# MK81F25615 register map
Vendor: Freescale Semiconductor, Inc.; Series: Kinetis_K; File version: 1.6
CPU: CM4 r0p1, little endian, no MPU, FPU, VTOR, 4 interrupt priority bits
Registers are 32-bit, read-write, reset 0x0 unless marked. A register's access mark holds for its fields unless they carry their own. Offsets are from the block's base; [hi:lo] are bit positions; {n}, {i} and the like mark numbered series; 'fields as' and 'values as' point back to an identical list.

## GPIOA — General Purpose Input/Output
Base 0x400FF000; register names take the prefix GPIOA_
0x00 PDOR — Port Data Output Register
  [31:0] PDO — Port Data Output
    0=Logic level 0 is driven on pin, provided pin is configured for general-purpose output; 1=Logic level 1 is driven on pin, provided pin is configured for general-purpose output
0x04 PSOR wo — Port Set Output Register
  [31:0] PTSO — Port Set Output
    0=Corresponding bit in PDORn does not change; 1=Corresponding bit in PDORn is set to logic 1
0x08 PCOR wo — Port Clear Output Register
  [31:0] PTCO — Port Clear Output
    0=Corresponding bit in PDORn does not change; 1=Corresponding bit in PDORn is cleared to logic 0
0x0C PTOR wo — Port Toggle Output Register
  [31:0] PTTO — Port Toggle Output
    0=Corresponding bit in PDORn does not change; 1=Corresponding bit in PDORn is set to the inverse of its existing logic state
0x10 PDIR ro — Port Data Input Register
  [31:0] PDI — Port Data Input
    0=Pin logic level is logic 0, or is not configured for use by digital function; 1=Pin logic level is logic 1
0x14 PDDR — Port Data Direction Register
  [31:0] PDD — Port Data Direction
    0=Pin is configured as general-purpose input, for the GPIO function; 1=Pin is configured as general-purpose output, for the GPIO function

## GPIOB — General Purpose Input/Output
Base 0x400FF040; register names take the prefix GPIOB_
Registers as GPIOA.

## GPIOC — General Purpose Input/Output
Base 0x400FF080; register names take the prefix GPIOC_
Registers as GPIOA.

## GPIOD — General Purpose Input/Output
Base 0x400FF0C0; register names take the prefix GPIOD_
Registers as GPIOA.

## GPIOE — General Purpose Input/Output
Base 0x400FF100; register names take the prefix GPIOE_
Registers as GPIOA.

## CAU — Memory Mapped Cryptographic Acceleration Unit (MMCAU)
Base 0xE0081000
{0x0+4i} CAU_DIRECT{i} wo (i=0..15) — Direct access register {i}
  [31:0] CAU_DIRECT{i} — Direct register {i}
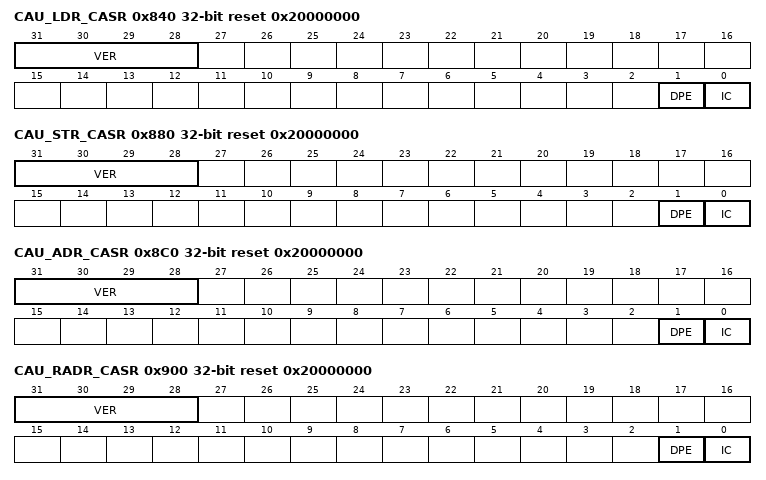
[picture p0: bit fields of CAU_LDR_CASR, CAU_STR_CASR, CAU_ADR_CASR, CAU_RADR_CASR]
0x840 CAU_LDR_CASR wo reset 0x20000000 — Status register - Load Register command
  [31:28] VER — CAU version
    1=Initial CAU version; 2=Second version, added support for SHA-256 algorithm.(This is the value on this device)
  [1] DPE
    0=No error detected; 1=DES key parity error detected
  [0] IC
    0=No illegal commands issued; 1=Illegal command issued
0x844 CAU_LDR_CAA wo — Accumulator register - Load Register command
  [31:0] ACC
{0x848+4i} CAU_LDR_CA{i} wo (i=0..8) — General Purpose Register {i} - Load Register command
0x880 CAU_STR_CASR ro reset 0x20000000 — Status register - Store Register command
  fields as CAU_LDR_CASR
0x884 CAU_STR_CAA ro — Accumulator register - Store Register command
  [31:0] ACC
{0x888+4i} CAU_STR_CA{i} ro (i=0..8) — General Purpose Register {i} - Store Register command
0x8C0 CAU_ADR_CASR wo reset 0x20000000 — Status register - Add Register command
  fields as CAU_LDR_CASR
0x8C4 CAU_ADR_CAA wo — Accumulator register - Add to register command
  [31:0] ACC
{0x8C8+4i} CAU_ADR_CA{i} wo (i=0..8) — General Purpose Register {i} - Add to register command
0x900 CAU_RADR_CASR wo reset 0x20000000 — Status register - Reverse and Add to Register command
  fields as CAU_LDR_CASR
0x904 CAU_RADR_CAA wo — Accumulator register - Reverse and Add to Register command
  [31:0] ACC
{0x908+4i} CAU_RADR_CA{i} wo (i=0..8) — General Purpose Register {i} - Reverse and Add to Register command
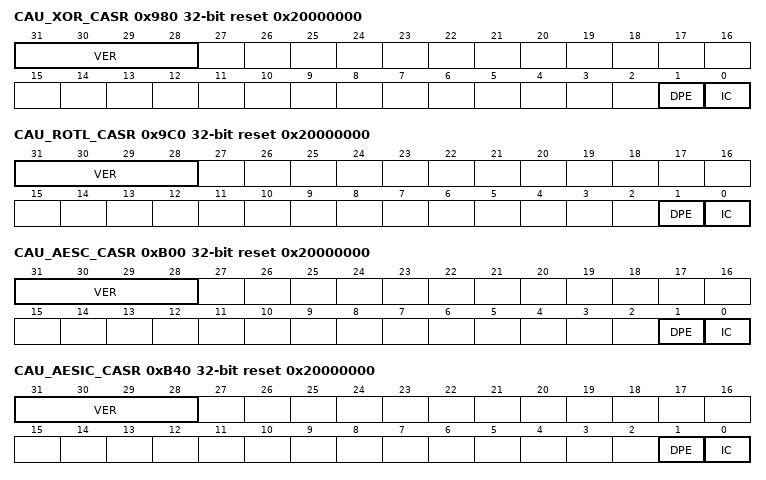
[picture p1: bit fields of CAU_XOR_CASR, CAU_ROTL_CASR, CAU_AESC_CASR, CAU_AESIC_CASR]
0x980 CAU_XOR_CASR wo reset 0x20000000 — Status register - Exclusive Or command
  fields as CAU_LDR_CASR
0x984 CAU_XOR_CAA wo — Accumulator register - Exclusive Or command
  [31:0] ACC
{0x988+4i} CAU_XOR_CA{i} wo (i=0..8) — General Purpose Register {i} - Exclusive Or command
0x9C0 CAU_ROTL_CASR wo reset 0x20000000 — Status register - Rotate Left command
  fields as CAU_LDR_CASR
0x9C4 CAU_ROTL_CAA wo — Accumulator register - Rotate Left command
  [31:0] ACC
{0x9C8+4i} CAU_ROTL_CA{i} wo (i=0..8) — General Purpose Register {i} - Rotate Left command
0xB00 CAU_AESC_CASR wo reset 0x20000000 — Status register - AES Column Operation command
  fields as CAU_LDR_CASR
0xB04 CAU_AESC_CAA wo — Accumulator register - AES Column Operation command
  [31:0] ACC
{0xB08+4i} CAU_AESC_CA{i} wo (i=0..8) — General Purpose Register {i} - AES Column Operation command
0xB40 CAU_AESIC_CASR wo reset 0x20000000 — Status register - AES Inverse Column Operation command
  fields as CAU_LDR_CASR
0xB44 CAU_AESIC_CAA wo — Accumulator register - AES Inverse Column Operation command
  [31:0] ACC
{0xB48+4i} CAU_AESIC_CA{i} wo (i=0..8) — General Purpose Register {i} - AES Inverse Column Operation command

## LMEM — Local Memory Controller
Base 0xE0082000; register names take the prefix LMEM_
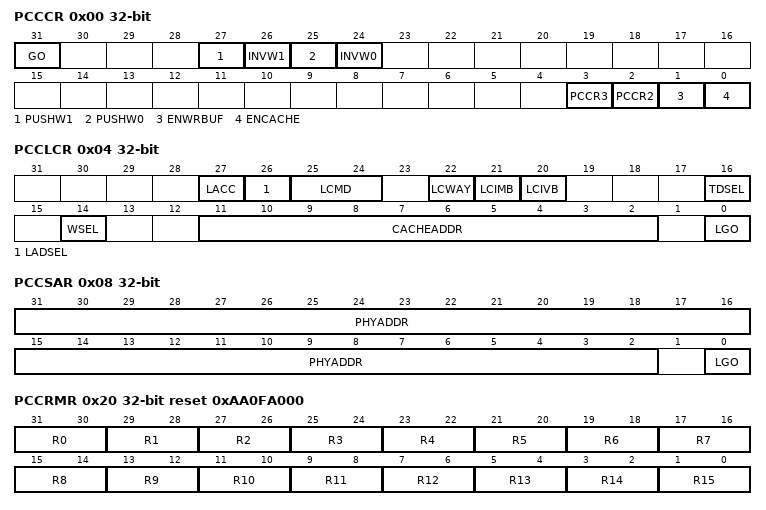
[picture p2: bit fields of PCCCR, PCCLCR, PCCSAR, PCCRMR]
0x00 PCCCR — Cache control register
  [31] GO — Initiate Cache Command
    0=Write: no effect. Read: no cache command active.; 1=Write: initiate command indicated by bits 27-24. Read: cache command active.
  [27] PUSHW1 — Push Way 1
    0=No operation; 1=When setting the GO bit, push all modified lines in way 1
  [26] INVW1 — Invalidate Way 1
    0=No operation; 1=When setting the GO bit, invalidate all lines in way 1
  [25] PUSHW0 — Push Way 0
    0=No operation; 1=When setting the GO bit, push all modified lines in way 0
  [24] INVW0 — Invalidate Way 0
    0=No operation; 1=When setting the GO bit, invalidate all lines in way 0
  [3] PCCR3 — Forces no allocation on cache misses (must also have PCCR2 asserted)
  [2] PCCR2 — Forces all cacheable spaces to write through
  [1] ENWRBUF — Enable Write Buffer
    0=Write buffer disabled; 1=Write buffer enabled
  [0] ENCACHE — Cache enable
    0=Cache disabled; 1=Cache enabled
0x04 PCCLCR — Cache line control register
  [27] LACC — Line access type
    0=Read; 1=Write
  [26] LADSEL — Line Address Select
    0=Cache address; 1=Physical address
  [25:24] LCMD — Line Command
    0=Search and read or write; 1=Invalidate; 2=Push; 3=Clear
  [22] LCWAY ro — Line Command Way
  [21] LCIMB ro — Line Command Initial Modified Bit
  [20] LCIVB ro — Line Command Initial Valid Bit
  [16] TDSEL — Tag/Data Select
    0=Data; 1=Tag
  [14] WSEL — Way select
    0=Way 0; 1=Way 1
  [11:2] CACHEADDR — Cache address
  [0] LGO — Initiate Cache Line Command
    0=Write: no effect. Read: no line command active.; 1=Write: initiate line command indicated by bits 27-24. Read: line command active.
0x08 PCCSAR — Cache search address register
  [31:2] PHYADDR — Physical Address
  [0] LGO — Initiate Cache Line Command
    0=Write: no effect. Read: no line command active.; 1=Write: initiate line command indicated by bits CLCR[27:24]. Read: line command active.
0x0C PCCCVR — Cache read/write value register
  [31:0] DATA — Cache read/write Data
0x20 PCCRMR reset 0xAA0FA000 — Cache regions mode register
  [all] fields
    0=Non-cacheable; 1=Non-cacheable; 2=Write-through; 3=Write-back
  [31-2n:30-2n] R{n} (n=0..15) — Region {n} mode
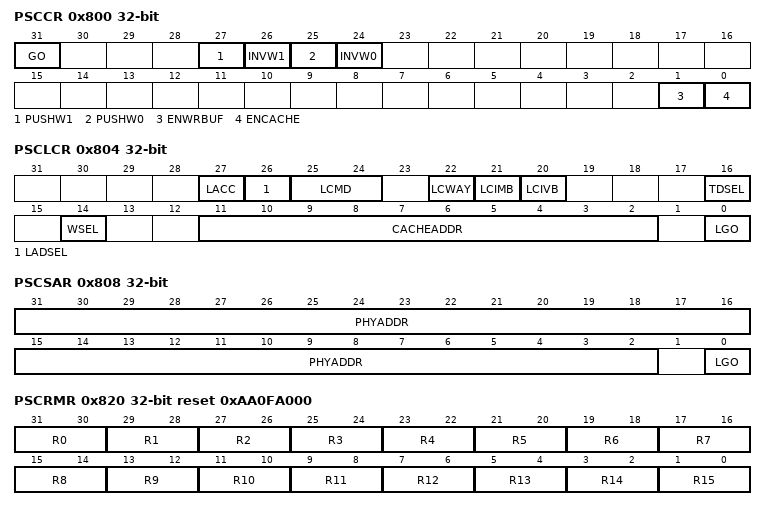
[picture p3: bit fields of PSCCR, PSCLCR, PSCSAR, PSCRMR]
0x800 PSCCR — Cache control register
  [31] GO — Initiate Cache Command
    values as PCCCR.GO
  [27] PUSHW1 — Push Way 1
    values as PCCCR.PUSHW1
  [26] INVW1 — Invalidate Way 1
    values as PCCCR.INVW1
  [25] PUSHW0 — Push Way 0
    values as PCCCR.PUSHW0
  [24] INVW0 — Invalidate Way 0
    values as PCCCR.INVW0
  [1] ENWRBUF — Enable Write Buffer
    0=Write buffer disabled; 1=Write buffer enabled
  [0] ENCACHE — Cache enable
    0=Cache disabled; 1=Cache enabled
0x804 PSCLCR — Cache line control register
  fields as PCCLCR
0x808 PSCSAR — Cache search address register
  fields as PCCSAR
0x80C PSCCVR — Cache read/write value register
  [31:0] DATA — Cache read/write Data
0x820 PSCRMR reset 0xAA0FA000 — Cache regions mode register
  fields as PCCRMR
